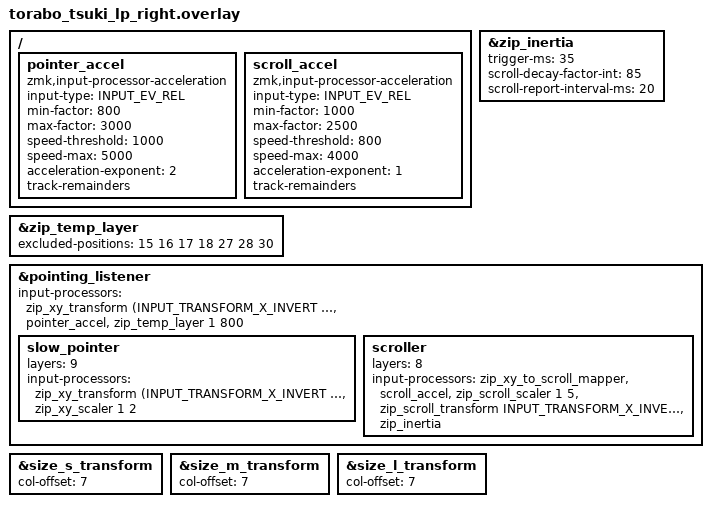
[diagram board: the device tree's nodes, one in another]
#include "torabo_tsuki_lp.dtsi"
#include <input/processors.dtsi>
#include <dt-bindings/zmk/input_transform.h>

/* --- 追加: 加速度と慣性モジュールのヘッダーインクルード --- */
#include <dt-bindings/zmk/pointing.h>
#include <zmk-input-inertia/input/processor/input_inertia.dtsi>

/* ===================================================
   1. 加速度パラメータの設定
   =================================================== */
/ {
    // マウスポインタ用 加速度ノード
    pointer_accel: pointer_accel {
        compatible = "zmk,input-processor-acceleration";
        #input-processor-cells = <0>;
        input-type = <INPUT_EV_REL>;
        min-factor = <800>;              // 低速時: 0.8倍 (精密操作)
        max-factor = <3000>;             // 高速時: 3.0倍 (素早い移動)
        speed-threshold = <1000>;        // 加速が始まり出す速度
        speed-max = <5000>;              // 最大加速に達する速度
        acceleration-exponent = <2>;     // カーブの強さ
        track-remainders;
    };

    // スクロール用 加速度ノード
    scroll_accel: scroll_accel {
        compatible = "zmk,input-processor-acceleration";
        #input-processor-cells = <0>;
        input-type = <INPUT_EV_REL>;
        min-factor = <1000>;             // 低速時: 1.0倍
        max-factor = <2500>;             // 高速時: 2.5倍
        speed-threshold = <800>;
        speed-max = <4000>;
        acceleration-exponent = <1>;
        track-remainders;
    };
};

/* ===================================================
   2. 慣性スクロール（モジュール定義済みノードの上書き）
   =================================================== */
&zip_inertia {
    trigger-ms = <35>;               // 慣性発動までの判定時間 (ms)
    scroll-decay-factor-int = <85>;  // 減衰率 (大きいほど長く滑る)
    scroll-report-interval-ms = <20>; // スクロールの更新間隔
};

&zip_temp_layer {
    excluded-positions = <
        15 // H copy
        16 // J left
        17 // K middle
        18 // L right
        27 // N paste
        28 // M prev
        30 // . next
    >;
};

&pointing_listener {
    input-processors = <
        &zip_xy_transform (INPUT_TRANSFORM_X_INVERT | INPUT_TRANSFORM_Y_INVERT)
        &pointer_accel                  // ← マウス移動に加速度を適用
        &zip_temp_layer 1 800
    >;
    //レイヤー1をオートマウスレイヤに設定　800msec有効

    slow_pointer {
        layers = <9>;
        input-processors = <
            &zip_xy_transform (INPUT_TRANSFORM_X_INVERT | INPUT_TRANSFORM_Y_INVERT)
            &zip_xy_scaler 1 2
        >;
    };

    scroller {
        layers = <8>;
        input-processors = <
            &zip_xy_to_scroll_mapper
            &scroll_accel               // ← スクロールに加速度を適用
            &zip_scroll_scaler 1 5
            &zip_scroll_transform INPUT_TRANSFORM_X_INVERT
            &zip_inertia                // ← 最尾に慣性処理を配置
        >;
    };
};

&size_s_transform {
    col-offset = <7>;
};

&size_m_transform {
    col-offset = <7>;
};

&size_l_transform {
    col-offset = <7>;
}; 
